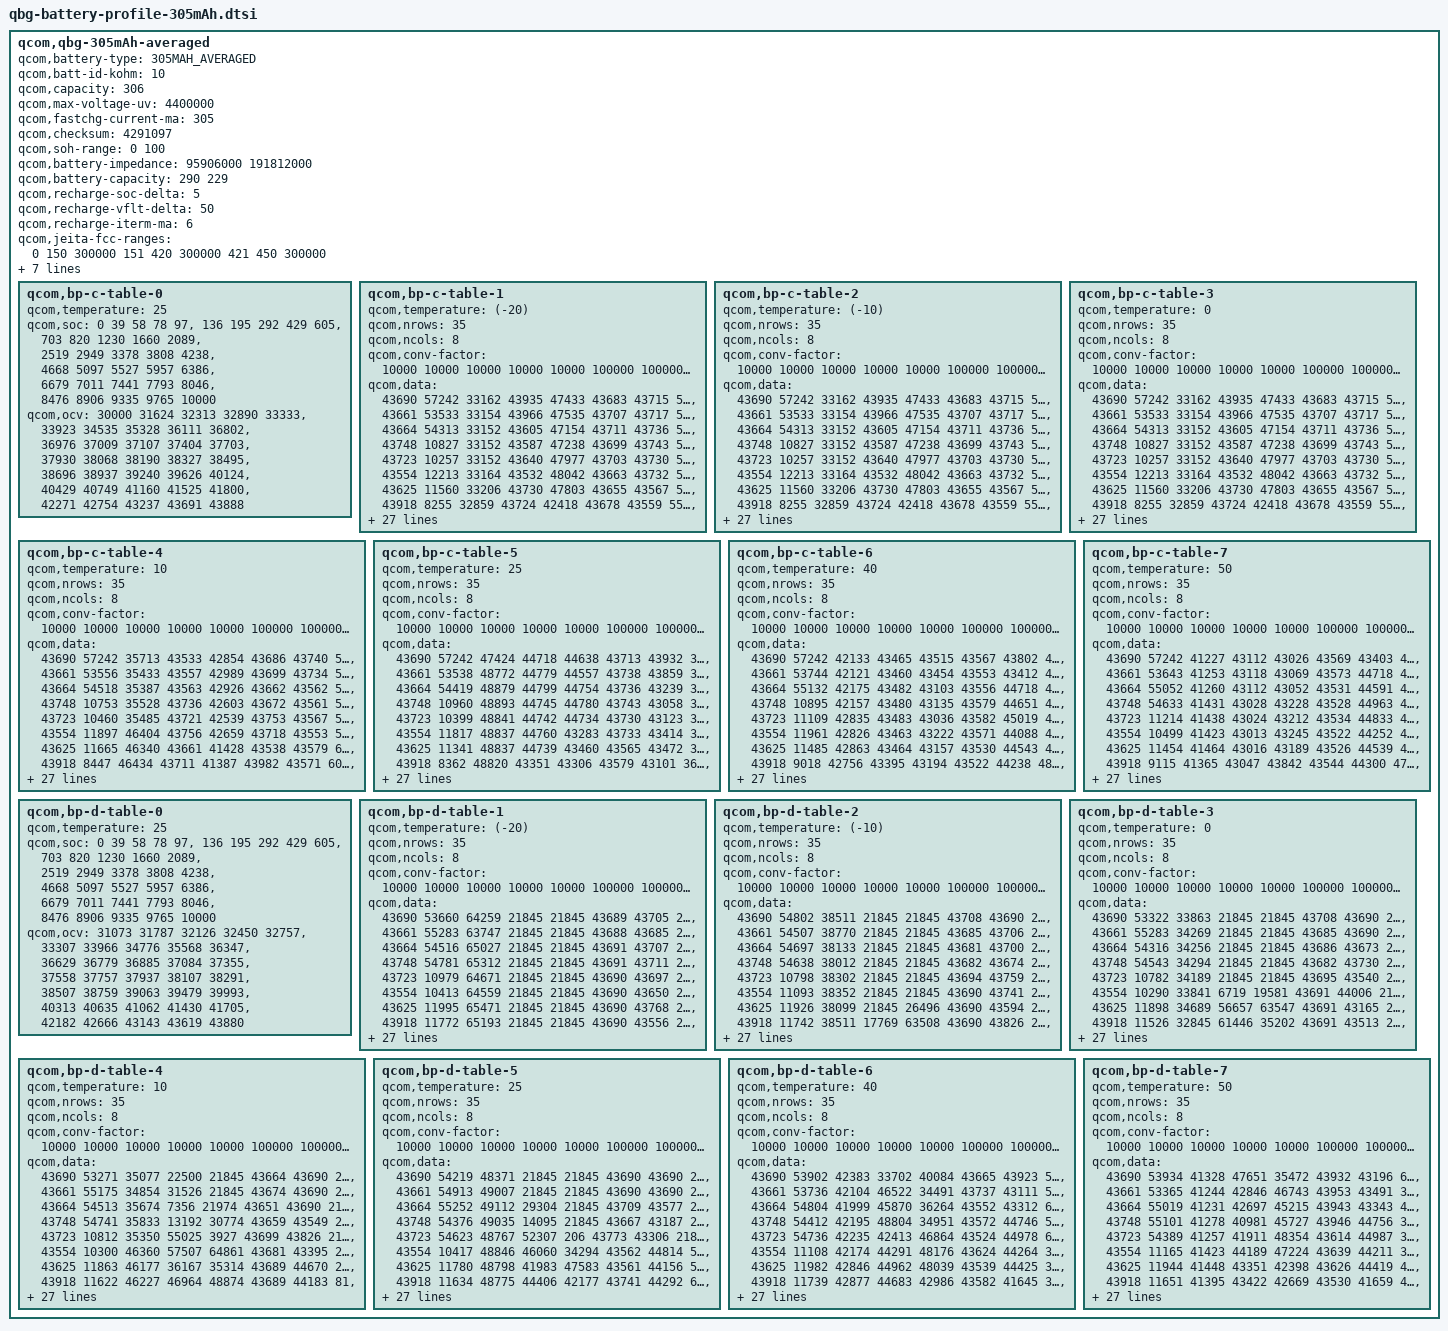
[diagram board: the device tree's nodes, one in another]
qcom,qbg-305mAh-averaged {
	qcom,battery-type = "305MAH_AVERAGED";
	qcom,batt-id-kohm = <10>;
	qcom,capacity = <306>;
	qcom,max-voltage-uv = <4400000>;
	qcom,fastchg-current-ma = <305>;
	qcom,checksum = <4291097>; /*@5, 0.005V, 4% */
	qcom,soh-range = <0 100>;
	/*Nominal_Impedance in 10nohm @ SOC 50% 25C* 0:fresh cell, 1: aged cell*/
	qcom,battery-impedance = <95906000 191812000>;
	/*Nominal_Capacity in mAh. 0: fresh cell, 1:aged cell*/
	qcom,battery-capacity = <290 229>;
	/*SOC delta (in percent) dropped from EOC SOC to enable recharge*/
	qcom,recharge-soc-delta =<5>;
	/*vfloat delta (in mV) dropped from regular vfloat in recharge*/
	qcom,recharge-vflt-delta =<50>;
	/*termination current (in mA) in recharge*/
	qcom,recharge-iterm-ma = <6>;

	qcom,jeita-fcc-ranges = <0  150 300000
				151 420 300000
				421 450 300000>;

	qcom,jeita-fv-ranges = <0  150 4350000
				151 420 4400000
				421 450 4350000>;

	qcom,jeita-soft-fcc-ua = <156000 200000>;
	qcom,jeita-soft-fv-uv = <4350000 4350000>;

	/* COOL = 15 DegC, WARM = 45 DegC */
	qcom,jeita-soft-thresholds = <0x084E 0x02F5>;
	/* COLD = 0 DegC, HOT = 45.1 DegC */
	qcom,jeita-hard-thresholds = <0x0E46 0x02F2>;
	/* COOL = 18 DegC, WARM = 44 DegC*/
	qcom,jeita-soft-hys-thresholds = <0x0775 0x030E>;

	qcom,bp-c-table-0 {
		qcom,temperature = <25>;
		qcom,soc = <    0    39    58    78    97>,
			<  136   195   292   429   605>,
			<  703   820  1230  1660  2089>,
			< 2519  2949  3378  3808  4238>,
			< 4668  5097  5527  5957  6386>,
			< 6679  7011  7441  7793  8046>,
			< 8476  8906  9335  9765 10000>;
		qcom,ocv = <30000 31624 32313 32890 33333>,
			<33923 34535 35328 36111 36802>,
			<36976 37009 37107 37404 37703>,
			<37930 38068 38190 38327 38495>,
			<38696 38937 39240 39626 40124>,
			<40429 40749 41160 41525 41800>,
			<42271 42754 43237 43691 43888>;
	};

	qcom,bp-c-table-1 {
		qcom,temperature = <(-20)>;
		qcom,nrows = <35>;
		qcom,ncols = <8>;
		qcom,conv-factor = <10000 10000 10000 10000 10000 100000 100000 10000>;
		qcom,data = <43690 57242 33162 43935 47433 43683 43715 55044>,
			<43661 53533 33154 43966 47535 43707 43717 53512>,
			<43664 54313 33152 43605 47154 43711 43736 53256>,
			<43748 10827 33152 43587 47238 43699 43743 54029>,
			<43723 10257 33152 43640 47977 43703 43730 53790>,
			<43554 12213 33164 43532 48042 43663 43732 56388>,
			<43625 11560 33206 43730 47803 43655 43567 56850>,
			<43918  8255 32859 43724 42418 43678 43559 55529>,
			<43783  9997 33173 43744 42220 43753 43583 56047>,
			<43255 15048 33252 43672 42915 43765 43581 50963>,
			<43029 14912 33276 43648 42942 43712 43576 50743>,
			<43422 15280 33244 43698 43005 43534 43579 49501>,
			<44644 15111 33212 43659 42051 43576 43570 50814>,
			<44246 14406 33270 43675 48101 43712 43577 50428>,
			<41603 16039 33087 43666 47963 43760 43570 50947>,
			<41853 15987 33222 43759 47130 43751 43577 50697>,
			<41263 16376 33173 43718 47602 43670 43579 49503>,
			<42904 16145 33183 43559 48866 43674 43579 50856>,
			<42058 15543 33257 43313 47326 43664 43994 51104>,
			<47652 15573 33214 42336 41919 43716 45031 50181>,
			<47254 15760 32774 47854 41975 43719 44905 50334>,
			<47427 12947 32811 42307 41914 43719 44978 50721>,
			<48957 13263 32831 42199 41777 43719 43504 49549>,
			<48623 12326 32865 42222 41119 43718 43129 49576>,
			<45656 12574 33192 42352 41210 43713 43476 49464>,
			<45245 13834 32976 47687 41196 43713 44793 49501>,
			<45513 14161 32968 47714 41132 43718 43331 49435>,
			<47035 13682 32986 47768 41794 43738 43116 49621>,
			<46299  3001 32780 47692 41445 43728 43037 50616>,
			<46532  2216 32855 48003 42610 43743 43021 55738>,
			<35766  2306 33037 47884 48090 43713 43202 55029>,
			<34912  4057 33124 47963 48182 43713 43196 11457>,
			<36573  3528 34768 41839 36598 43753 43935 15406>,
			<35983  1015 34644 43082 33289 43655 43549  2911>,
			<36282   225 34228 43555 35807 43657 43740 13762>;
	};

	qcom,bp-c-table-2 {
		qcom,temperature = <(-10)>;
		qcom,nrows = <35>;
		qcom,ncols = <8>;
		qcom,conv-factor = <10000 10000 10000 10000 10000 100000 100000 10000>;
		qcom,data = <43690 57242 33162 43935 47433 43683 43715 55044>,
			<43661 53533 33154 43966 47535 43707 43717 53512>,
			<43664 54313 33152 43605 47154 43711 43736 53256>,
			<43748 10827 33152 43587 47238 43699 43743 54029>,
			<43723 10257 33152 43640 47977 43703 43730 53790>,
			<43554 12213 33164 43532 48042 43663 43732 56388>,
			<43625 11560 33206 43730 47803 43655 43567 56850>,
			<43918  8255 32859 43724 42418 43678 43559 55529>,
			<43783  9997 33173 43744 42220 43753 43583 56047>,
			<43255 15048 33252 43672 42915 43765 43581 50963>,
			<43029 14912 33276 43648 42942 43712 43576 50743>,
			<43422 15280 33244 43698 43005 43534 43579 49501>,
			<44644 15111 33212 43659 42051 43576 43570 50814>,
			<44246 14406 33270 43675 48101 43712 43577 50428>,
			<41603 16039 33087 43666 47963 43760 43570 50947>,
			<41853 15987 33222 43759 47130 43751 43577 50697>,
			<41263 16376 33173 43718 47602 43670 43579 49503>,
			<42904 16145 33183 43559 48866 43674 43579 50856>,
			<42058 15543 33257 43313 47326 43664 43994 51104>,
			<47652 15573 33214 42336 41919 43716 45031 50181>,
			<47254 15760 32774 47854 41975 43719 44905 50334>,
			<47427 12947 32811 42307 41914 43719 44978 50721>,
			<48957 13263 32831 42199 41777 43719 43504 49549>,
			<48623 12326 32865 42222 41119 43718 43129 49576>,
			<45656 12574 33192 42352 41210 43713 43476 49464>,
			<45245 13834 32976 47687 41196 43713 44793 49501>,
			<45513 14161 32968 47714 41132 43718 43331 49435>,
			<47035 13682 32986 47768 41794 43738 43116 49621>,
			<46299  3001 32780 47692 41445 43728 43037 50616>,
			<46532  2216 32855 48003 42610 43743 43021 55738>,
			<35766  2306 33037 47884 48090 43713 43202 55029>,
			<34912  4057 33124 47963 48182 43713 43196 11457>,
			<36573  3528 34768 41839 36598 43753 43935 15406>,
			<35983  1015 34644 43082 33289 43655 43549  2911>,
			<36282   225 34228 43555 35807 43657 43740 13762>;
	};

	qcom,bp-c-table-3 {
		qcom,temperature = <0>;
		qcom,nrows = <35>;
		qcom,ncols = <8>;
		qcom,conv-factor = <10000 10000 10000 10000 10000 100000 100000 10000>;
		qcom,data = <43690 57242 33162 43935 47433 43683 43715 55044>,
			<43661 53533 33154 43966 47535 43707 43717 53512>,
			<43664 54313 33152 43605 47154 43711 43736 53256>,
			<43748 10827 33152 43587 47238 43699 43743 54029>,
			<43723 10257 33152 43640 47977 43703 43730 53790>,
			<43554 12213 33164 43532 48042 43663 43732 56388>,
			<43625 11560 33206 43730 47803 43655 43567 56850>,
			<43918  8255 32859 43724 42418 43678 43559 55529>,
			<43783  9997 33173 43744 42220 43753 43583 56047>,
			<43255 15048 33252 43672 42915 43765 43581 50963>,
			<43029 14912 33276 43648 42942 43712 43576 50743>,
			<43422 15280 33244 43698 43005 43534 43579 49501>,
			<44644 15111 33212 43659 42051 43576 43570 50814>,
			<44246 14406 33270 43675 48101 43712 43577 50428>,
			<41603 16039 33087 43666 47963 43760 43570 50947>,
			<41853 15987 33222 43759 47130 43751 43577 50697>,
			<41263 16376 33173 43718 47602 43670 43579 49503>,
			<42904 16145 33183 43559 48866 43674 43579 50856>,
			<42058 15543 33257 43313 47326 43664 43994 51104>,
			<47652 15573 33214 42336 41919 43716 45031 50181>,
			<47254 15760 32774 47854 41975 43719 44905 50334>,
			<47427 12947 32811 42307 41914 43719 44978 50721>,
			<48957 13263 32831 42199 41777 43719 43504 49549>,
			<48623 12326 32865 42222 41119 43718 43129 49576>,
			<45656 12574 33192 42352 41210 43713 43476 49464>,
			<45245 13834 32976 47687 41196 43713 44793 49501>,
			<45513 14161 32968 47714 41132 43718 43331 49435>,
			<47035 13682 32986 47768 41794 43738 43116 49621>,
			<46299  3001 32780 47692 41445 43728 43037 50616>,
			<46532  2216 32855 48003 42610 43743 43021 55738>,
			<35766  2306 33037 47884 48090 43713 43202 55029>,
			<34912  4057 33124 47963 48182 43713 43196 11457>,
			<36573  3528 34768 41839 36598 43753 43935 15406>,
			<35983  1015 34644 43082 33289 43655 43549  2911>,
			<36282   225 34228 43555 35807 43657 43740 13762>;
	};

	qcom,bp-c-table-4 {
		qcom,temperature = <10>;
		qcom,nrows = <35>;
		qcom,ncols = <8>;
		qcom,conv-factor = <10000 10000 10000 10000 10000 100000 100000 10000>;
		qcom,data = <43690 57242 35713 43533 42854 43686 43740 58470>,
			<43661 53556 35433 43557 42989 43699 43734 59267>,
			<43664 54518 35387 43563 42926 43662 43562 59135>,
			<43748 10753 35528 43736 42603 43672 43561 57641>,
			<43723 10460 35485 43721 42539 43753 43567 57373>,
			<43554 11897 46404 43756 42659 43718 43553 58261>,
			<43625 11665 46340 43661 41428 43538 43579 60704>,
			<43918  8447 46434 43711 41387 43982 43571 60589>,
			<43783 10183 46336 43694 41015 43442 43531 61136>,
			<43255 14983 46394 43688 41822 44783 43522 59466>,
			<43029 14959 46578 43688 41738 44688 43575 60224>,
			<43422 14916 46572 43688 41841 44668 43569 60206>,
			<44644 15297 46473 43154 41827 43968 43898 59625>,
			<44246 14545 46519 41863 44885 43565 44059 61155>,
			<41603 14603 46465 41969 44264 43555 44443 59728>,
			<41853 15908 46160 41731 44193 43564 44152 59493>,
			<41263 16302 46146 41855 44208 43566 44248 60287>,
			<42904 16321 46147 41128 44185 43560 44175 60369>,
			<42058 16244 46195 41167 44231 43733 44196 60193>,
			<47652 15553 46086 40980 44460 43732 44897 60252>,
			<47254 15805 46122 41038 41679 43732 44945 59515>,
			<47427 15733 46090 41394 40998 43733 44919 60971>,
			<48957 12885 46209 41392 41024 43729 44372 61171>,
			<48623 12311 46929 41005 44104 43732 44202 38362>,
			<45656 13978 46956 40966 44239 43562 44805 38105>,
			<45245 14211 46877 41087 44138 43562 44908 37920>,
			<45513 13328 46951 41832 44210 43563 43332 38848>,
			<47035  2810 46915 41197 44171 43733 44773 38140>,
			<46299  2877 46940 41060 44251 43735 44757 38162>,
			<46532  2102 46967 41028 44132 43734 44699 60127>,
			<35766  3788 46899 41229 44332 43728 44696 59634>,
			<34912  3220 46902 42649 41815 43731 43281 60675>,
			<36573   648 46929 42683 47850 43729 43008 63899>,
			<35983   852 46174 41925 48379 43729 43882 63418>,
			<36282    91 35476 44681 48555 43767 43633 63337>;
	};

	qcom,bp-c-table-5 {
		qcom,temperature = <25>;
		qcom,nrows = <35>;
		qcom,ncols = <8>;
		qcom,conv-factor = <10000 10000 10000 10000 10000 100000 100000 10000>;
		qcom,data = <43690 57242 47424 44718 44638 43713 43932 32945>,
			<43661 53538 48772 44779 44557 43738 43859 33766>,
			<43664 54419 48879 44799 44754 43736 43239 33357>,
			<43748 10960 48893 44745 44780 43743 43058 33321>,
			<43723 10399 48841 44742 44734 43730 43123 33420>,
			<43554 11817 48837 44760 43283 43733 43414 36316>,
			<43625 11341 48837 44739 43460 43565 43472 35895>,
			<43918  8362 48820 43351 43306 43579 43101 36612>,
			<43783 10149 47437 44558 43115 43569 44623 36431>,
			<43255  9576 47361 44796 43126 43534 44740 36530>,
			<43029 15066 47384 44779 43219 43530 44973 35269>,
			<43422 14907 47362 44791 43040 43575 45000 35300>,
			<44644 14937 47581 44976 44675 43572 44817 36477>,
			<44246 14518 47607 44832 44646 43575 44139 36825>,
			<41603 14829 47612 44851 44981 43572 44427 36804>,
			<41853 16000 47591 44205 45009 43571 44316 36727>,
			<41263 15902 47491 44160 45030 43581 41713 36840>,
			<42904 16260 47534 44170 44974 43580 44315 36600>,
			<42058 16157 47218 44180 44627 43577 44433 35157>,
			<47652 15605 47200 44244 44964 43557 44078 36539>,
			<47254 15746 47208 44152 44842 43559 44834 36406>,
			<47427 12979 47130 44475 44094 43559 44649 36707>,
			<48957 13282 47165 44477 44383 43578 44742 35937>,
			<48623 12384 47311 44075 41502 43576 44177 36037>,
			<45656 13846 47311 44871 44570 43582 45041 35617>,
			<45245 14151 47307 44871 44732 43582 45041 35757>,
			<45513 13703 47346 44887 43346 43582 45009 35411>,
			<47035  2658 47334 44223 44770 43583 44928 35778>,
			<46299  2207 47252 44214 44592 43583 44597 35653>,
			<46532  2530 47263 44173 44660 43582 44756 35019>,
			<35766  4021 47258 44247 45002 43582 44552 35223>,
			<34912  3496 47294 44145 44204 43582 44556 36572>,
			<36573   591 47320 44427 41595 43577 43373 33328>,
			<35983     1 47539 44668 42550 43557 43855 34343>,
			<36282   474 48838 44588 41374 43731 43829 34533>;
	};

	qcom,bp-c-table-6 {
		qcom,temperature = <40>;
		qcom,nrows = <35>;
		qcom,ncols = <8>;
		qcom,conv-factor = <10000 10000 10000 10000 10000 100000 100000 10000>;
		qcom,data = <43690 57242 42133 43465 43515 43567 43802 48586>,
			<43661 53744 42121 43460 43454 43553 43412 48219>,
			<43664 55132 42175 43482 43103 43556 44718 48145>,
			<43748 10895 42157 43480 43135 43579 44651 48173>,
			<43723 11109 42835 43483 43036 43582 45019 48382>,
			<43554 11961 42826 43463 43222 43571 44088 48990>,
			<43625 11485 42863 43464 43157 43530 44543 49119>,
			<43918  9018 42756 43395 43194 43522 44238 48736>,
			<43783  9743 42793 43101 43187 43527 45015 48840>,
			<43255  9712 42945 43106 43190 43548 44988 47445>,
			<43029 15030 42959 43052 43868 43542 44978 47404>,
			<43422 15083 42993 43063 43842 43551 44818 47400>,
			<44644 14899 42987 43429 43500 43549 44559 49054>,
			<44246 15214 42905 43400 43517 43550 44858 49031>,
			<41603 14415 42891 43470 43319 43536 44101 48933>,
			<41853 14691 42919 43309 43271 43546 44465 48897>,
			<41263 16065 42587 43476 43270 43547 44430 49115>,
			<42904 15940 42619 43313 43465 43524 44328 49077>,
			<42058 16174 42503 43282 43508 43522 44154 49083>,
			<47652 15504 42537 43328 43475 43529 44913 49043>,
			<47254 15804 42712 44723 43377 43528 44652 48924>,
			<47427 12938 42697 44686 44753 43529 43356 48381>,
			<48957 13252 42721 44711 44636 43533 43314 48188>,
			<48623 12731 42730 43320 44638 43526 43323 48981>,
			<45656 13916 42629 43496 43009 43533 44948 47599>,
			<45245 13475 42637 43415 43008 43520 44963 47506>,
			<45513 13801 42637 43412 43026 43521 44561 47593>,
			<47035  2655 42628 43490 43448 43520 44769 47365>,
			<46299  2267 42629 43492 43471 43526 43329 48828>,
			<46532  2349 42653 43472 43320 43524 44685 48683>,
			<35766  4035 42723 43361 43332 43525 44756 49145>,
			<34912  3576 42751 43382 44583 43525 44730 48304>,
			<36573   902 42695 44672 44941 43544 44769 48514>,
			<35983   114 42608 43313 41563 43526 43115 45139>,
			<36282   265 42141 43253 44158 43539 43805 45990>;
	};

	qcom,bp-c-table-7 {
		qcom,temperature = <50>;
		qcom,nrows = <35>;
		qcom,ncols = <8>;
		qcom,conv-factor = <10000 10000 10000 10000 10000 100000 100000 10000>;
		qcom,data = <43690 57242 41227 43112 43026 43569 43403 47305>,
			<43661 53643 41253 43118 43069 43573 44718 47282>,
			<43664 55052 41260 43112 43052 43531 44591 47961>,
			<43748 54633 41431 43028 43228 43528 44963 47994>,
			<43723 11214 41438 43024 43212 43534 44833 47879>,
			<43554 10499 41423 43013 43245 43522 44252 48070>,
			<43625 11454 41464 43016 43189 43526 44539 48063>,
			<43918  9115 41365 43047 43842 43544 44300 47627>,
			<43783  9955 41355 43217 43878 43551 44289 47845>,
			<43255  9634 41377 43213 43781 43627 44387 42320>,
			<43029  9585 41387 43196 43824 43616 44109 42287>,
			<43422 15021 41055 43860 43825 43619 44105 42434>,
			<44644 15092 41029 43230 43025 43631 44641 47702>,
			<44246 15150 41034 43200 43033 43625 44918 47734>,
			<41603 14337 41086 43203 43089 43616 44202 48056>,
			<41853 14628 41064 43218 43402 43627 44887 48025>,
			<41263 16022 40975 43209 43396 43625 44811 48045>,
			<42904 15995 41005 43042 43027 43536 44082 47625>,
			<42058 16346 41176 43022 43119 43551 44900 47636>,
			<47652 15492 41162 43114 43434 43524 44571 48033>,
			<47254 15803 41188 43105 43481 43524 43279 47915>,
			<47427 12943 41108 43121 43378 43546 43519 47937>,
			<48957 13265 41093 43122 43333 43545 43501 47966>,
			<48623 12682 41097 43219 43300 43538 43458 48045>,
			<45656 13904 41138 43190 43157 43541 44746 42470>,
			<45245 13484 41150 43187 43232 43624 44726 42491>,
			<45513 13806 41145 43166 43254 43627 44768 42451>,
			<47035  2647 41139 43225 43044 43626 44548 42323>,
			<46299  2257 41096 43055 43125 43540 44738 47861>,
			<46532  2367 41102 43042 43407 43541 44686 47621>,
			<35766  4054 41088 43060 43320 43543 43359 48021>,
			<34912  3528 41112 43108 43329 43537 44681 47997>,
			<36573   914 41108 43094 44581 43626 44686 47213>,
			<35983   117 40995 43438 44225 43624 43457 48705>,
			<36282   263 41340 43829 44176 43645 43807 48659>;
	};

	qcom,bp-d-table-0 {
		qcom,temperature = <25>;
		qcom,soc = <    0    39    58    78    97>,
			<  136   195   292   429   605>,
			<  703   820  1230  1660  2089>,
			< 2519  2949  3378  3808  4238>,
			< 4668  5097  5527  5957  6386>,
			< 6679  7011  7441  7793  8046>,
			< 8476  8906  9335  9765 10000>;
		qcom,ocv = <31073 31787 32126 32450 32757>,
			<33307 33966 34776 35568 36347>,
			<36629 36779 36885 37084 37355>,
			<37558 37757 37937 38107 38291>,
			<38507 38759 39063 39479 39993>,
			<40313 40635 41062 41430 41705>,
			<42182 42666 43143 43619 43880>;
	};

	qcom,bp-d-table-1 {
		qcom,temperature = <(-20)>;
		qcom,nrows = <35>;
		qcom,ncols = <8>;
		qcom,conv-factor = <10000 10000 10000 10000 10000 100000 100000 10000>;
		qcom,data = <43690 53660 64259 21845 21845 43689 43705 21845>,
			<43661 55283 63747 21845 21845 43688 43685 21845>,
			<43664 54516 65027 21845 21845 43691 43707 21845>,
			<43748 54781 65312 21845 21845 43691 43711 21845>,
			<43723 10979 64671 21845 21845 43690 43697 21845>,
			<43554 10413 64559 21845 21845 43690 43650 21845>,
			<43625 11995 65471 21845 21845 43690 43768 21845>,
			<43918 11772 65193 21845 21845 43690 43556 21845>,
			<43783  9046 63525 21845 12654 43690 43541 21845>,
			<43255  9875 64334 21845 62536 43690 43642 21845>,
			<43029 10122 64245 21845 64090 43690 43632 21845>,
			<43422 10052 58432 21845 61360 43690 43646 21845>,
			<44644  9577 58479 21845 60678 43690 43941 21845>,
			<44246 14944 58905 21845 37937 43690 43613 21845>,
			<41603 15156 57646 21845 38947 43690 43936 21845>,
			<41853 14584 57594 30648 33702 43691 43917 21845>,
			<41263 14427 60725 27562 36567 43691 43908 21845>,
			<42904 14628 60593  3502 35555 43691 44003 21845>,
			<42058 16013 60942  9504 46887 43691 44024 21845>,
			<47652 15979 59707 54774 45349 43691 44020 21845>,
			<47254 16375 59901 55359 45899 43691 43992 21845>,
			<47427 16213 59745 52773 45785 43691 43987 21845>,
			<48957 15390 59604 61929 48535 43691 43813 21845>,
			<48623 15678 59596 61556 48189 43691 43885 21845>,
			<45656 12909 60290 61479 48571 43691 43146 21845>,
			<45245 13157 59995 61550 45702 43691 43256 21845>,
			<45513 12699 59988 63155 45060 43691 43042 21845>,
			<47035 14233 60017 52167 46878 43691 43300 21845>,
			<46299 13643 60023 49709 33362 43691 44591 21845>,
			<46532  3038 59973 49605 33792 43691 44671 21845>,
			<35766  2091 60209 49630 33206 43691 43171 21845>,
			<34912  3638 60014 53309 35892 43691 43236 21845>,
			<36573  3469 59923  8750 35237 43691 43149 21845>,
			<35983   186 60411 14552 35339 43691 43993 21845>,
			<36282   379 60263 15528 46403 43691 43599 21845>;
	};

	qcom,bp-d-table-2 {
		qcom,temperature = <(-10)>;
		qcom,nrows = <35>;
		qcom,ncols = <8>;
		qcom,conv-factor = <10000 10000 10000 10000 10000 100000 100000 10000>;
		qcom,data = <43690 54802 38511 21845 21845 43708 43690 21845>,
			<43661 54507 38770 21845 21845 43685 43706 21845>,
			<43664 54697 38133 21845 21845 43681 43700 21845>,
			<43748 54638 38012 21845 21845 43682 43674 21845>,
			<43723 10798 38302 21845 21845 43694 43759 21845>,
			<43554 11093 38352 21845 21845 43690 43741 21845>,
			<43625 11926 38099 21845 26496 43690 43594 21845>,
			<43918 11742 38511 17769 63508 43690 43826 21845>,
			<43783  8197 36957  6979 33067 43690 43253 21845>,
			<43255 10134 37434 11872 46839 43691 43115 21845>,
			<43029  9351 40418 55369 45818 43691 43080 21845>,
			<43422  9308 40097 53114 48256 43691 43116 21845>,
			<44644 15047 40617 51903 45701 43691 43232 21845>,
			<44246 15336 39176 63993 47360 43691 43165 21845>,
			<41603 15195 39341 57419 47910 43691 43195 21845>,
			<41853 14393 40628 60164 47721 43691 43851 21845>,
			<41263 14745 39321 38593 47752 43688 43865 21845>,
			<42904 14701 39386 40090 47661 43688 43880 21678>,
			<42058 16115 40618 39879 47661 43688 43805 23876>,
			<47652 15943 39269 34621 47760 43688 43797 22748>,
			<47254 16163 39392 32897 47752 43688 43880 17639>,
			<47427 15509 39233 33481 47846 43688 43883 17982>,
			<48957 15770 40653 33286 42310 43688 43143 17979>,
			<48623 13013 39191 33379 47966 43688 43066 18219>,
			<45656 13140 39385 33336 48818 43688 43220 17499>,
			<45245 12787 39380 32865 48374 43688 43413 22649>,
			<45513 14314 39185 39738 45069 43688 44835 22280>,
			<47035 13569 39340 39696 36710 43688 43349 21845>,
			<46299  2657 39328 38978 36513 43688 43041 21845>,
			<46532  2853 39348 40563 35809 43688 43194 21845>,
			<35766  2519 39310 38436 46217 43688 43221 21845>,
			<34912  3883 38978 61153 46097 43688 43206 21845>,
			<36573  3351 39018 58953 46669 43688 43165 21845>,
			<35983   149 38922 64705 48475 43691 43892 21845>,
			<36282   278 38920 61786 48986 43691 43803 21845>;
	};

	qcom,bp-d-table-3 {
		qcom,temperature = <0>;
		qcom,nrows = <35>;
		qcom,ncols = <8>;
		qcom,conv-factor = <10000 10000 10000 10000 10000 100000 100000 10000>;
		qcom,data = <43690 53322 33863 21845 21845 43708 43690 21845>,
			<43661 55283 34269 21845 21845 43685 43690 21845>,
			<43664 54316 34256 21845 21845 43686 43673 21845>,
			<43748 54543 34294 21845 21845 43682 43730 21845>,
			<43723 10782 34189 21845 21845 43695 43540 21845>,
			<43554 10290 33841  6719 19581 43691 44006 21845>,
			<43625 11898 34689 56657 63547 43691 43165 21845>,
			<43918 11526 32845 61446 35202 43691 43513 21845>,
			<43783  8312 33572 38179 48098 43691 43379 21594>,
			<43255 10006 33686 40556 42268 43691 44774 17106>,
			<43029  9219 33700 39137 42289 43691 43343 20084>,
			<43422  9717 33316 34286 42425 43691 43404 19116>,
			<44644 15062 36217 39155 42200 43691 43256 19098>,
			<44246 15246 36132 33160 41293 43691 43188 30752>,
			<41603 15172 33415 36549 41325 43688 43232 27956>,
			<41853 14444 36216 46143 42557 43688 43050  5309>,
			<41263 14786 33442 45669 42558 43688 43236  7830>,
			<42904 14683 36160 48664 42559 43688 43197  1950>,
			<42058 16088 36183 47657 42931 43689 43881   701>,
			<47652 15953 33454 42987 42970 43689 43791  2362>,
			<47254 16138 36198 42505 42912 43689 43881 13587>,
			<47427 15403 36193 42244 42639 43689 43226 14166>,
			<48957 15645 33414 47258 42212 43694 43127 13661>,
			<48623 13232 33411 48814 47742 43694 43123  2532>,
			<45656 12343 33436 48939 47339 43692 43131  3977>,
			<45245 14050 33522 48174 48368 43701 43319   311>,
			<45513 13314 33323 48604 46167 43721 44868  4246>,
			<47035 13695 36319 48194 46605 43774 43038  7383>,
			<46299  2962 36155 46822 48393 43750 43361  4642>,
			<46532  2301 36101 46419 49096 43756 44559  4387>,
			<35766  3748 36350 46384 48252 43678 43504  5425>,
			<34912  3246 36279 35769 48415 43675 43440 28174>,
			<36573   672 36322 36309 48558 43699 43048 24705>,
			<35983   237 36172 39178 48677 43690 43998 31375>,
			<36282   309 33509 37768 47195 43690 43585 31013>;
	};

	qcom,bp-d-table-4 {
		qcom,temperature = <10>;
		qcom,nrows = <35>;
		qcom,ncols = <8>;
		qcom,conv-factor = <10000 10000 10000 10000 10000 100000 100000 10000>;
		qcom,data = <43690 53271 35077 22500 21845 43664 43690 21845>,
			<43661 55175 34854 31526 21845 43674 43690 21845>,
			<43664 54513 35674  7356 21974 43651 43690 21845>,
			<43748 54741 35833 13192 30774 43659 43549 21845>,
			<43723 10812 35350 55025  3927 43699 43826 21845>,
			<43554 10300 46360 57507 64861 43681 43395 21845>,
			<43625 11863 46177 36167 35314 43689 44670 26318>,
			<43918 11622 46227 46964 48874 43689 44183    81>,
			<43783  8301 46261 48620 42875 43689 44663 12523>,
			<43255 10014 46935 48002 42614 43689 43488 10129>,
			<43029  9339 46959 47988 42924 43694 43290  8490>,
			<43422  9513 46873 42332 42530 43694 43123  8719>,
			<44644 15085 46992 42601 41093 43694 43235 11942>,
			<44246 15272 47011 42578 41498 43693 43084 56599>,
			<41603 14504 46976 41110 41773 43709 43434 50432>,
			<41853 14414 47078 41145 44352 43743 44210 50116>,
			<41263 14810 47081 41943 44097 43734 45020 51453>,
			<42904 14709 47050 41679 44258 43563 44716 61813>,
			<42058 16074 47007 41703 44806 43560 44710 64931>,
			<47652 16266 47030 41560 44198 43560 44912 64648>,
			<47254 15540 47094 41735 41641 43561 44444 64959>,
			<47427 15805 47101 41149 41538 43554 44211 64920>,
			<48957 13036 46985 41384 41127 43560 44825 62142>,
			<48623 13062 47037 42658 41218 43734 45033 61588>,
			<45656 12751 47060 42824 42219 43741 44812 62670>,
			<45245 13944 47059 41996 47951 43743 45024 51312>,
			<45513 13374 47012 42380 48566 43736 43300 52568>,
			<47035  2737 46709 47294 47275 43721 43488 52316>,
			<46299  3028 46710 47279 48111 43773 43420 52578>,
			<46532  2104 46708 47987 48038 43769 43416 50102>,
			<35766  3800 47020 47296 47747 43775 43298 49554>,
			<34912  3273 47018 47150 47850 43768 43463 51026>,
			<36573   767 46689 47245 42096 43751 43415 50437>,
			<35983   245 46837 48031 41435 43757 43095 55964>,
			<36282   289 46721 47688 41007 43753 43133 50459>;
	};

	qcom,bp-d-table-5 {
		qcom,temperature = <25>;
		qcom,nrows = <35>;
		qcom,ncols = <8>;
		qcom,conv-factor = <10000 10000 10000 10000 10000 100000 100000 10000>;
		qcom,data = <43690 54219 48371 21845 21845 43690 43690 21845>,
			<43661 54913 49007 21845 21845 43690 43690 21845>,
			<43664 55252 49112 29304 21845 43709 43577 21845>,
			<43748 54376 49035 14095 21845 43667 43187 21845>,
			<43723 54623 48767 52307   206 43773 43306 21845>,
			<43554 10417 48846 46060 34294 43562 44814 56827>,
			<43625 11780 48798 41983 47583 43561 44156 58008>,
			<43918 11634 48775 44406 42177 43741 44292 60060>,
			<43783  8282 47486 44470 41913 43729 44378 37438>,
			<43255 10065 47457 44045 44442 43565 44323 39292>,
			<43029  9663 47397 44133 44300 43552 44125 39294>,
			<43422  9473 47413 44057 44266 43554 44902 39755>,
			<44644 15039 47405 45020 44676 43567 44643 34664>,
			<44246 14966 47593 44942 44777 43577 44610 32807>,
			<41603 15169 47563 44934 44714 43569 44915 33463>,
			<41853 14364 47196 44965 43367 43530 44240 36070>,
			<41263 14807 47547 45004 44663 43573 44377 36281>,
			<42904 16027 47521 45021 44816 43529 44536 36227>,
			<42058 15985 47531 45012 44861 43528 44256 35896>,
			<47652 16185 47223 44836 44985 43530 44198 36654>,
			<47254 15553 47208 44813 44649 43572 44186 36449>,
			<47427 15821 47215 44816 44547 43569 44283 36566>,
			<48957 12861 47116 44925 44985 43570 44198 36429>,
			<48623 12445 47104 44071 44510 43581 44894 36162>,
			<45656 13971 47315 44434 41441 43580 44690 34454>,
			<45245 14291 47301 44332 41440 43577 43519 34545>,
			<45513 13329 47322 44393 41915 43554 43076 32803>,
			<47035  2764 47302 44387 44525 43560 43320 33769>,
			<46299  2940 47308 44296 44042 43563 44707 33307>,
			<46532  2115 47307 44504 44239 43563 44773 33501>,
			<35766  3692 47301 44425 44179 43564 44569 33511>,
			<34912  3072 47308 44128 44275 43555 44553 33335>,
			<36573   557 47142 44248 44167 43556 44760 33295>,
			<35983   201 47174 44214 44810 43582 44682 33493>,
			<36282   450 47543 44888 45049 43581 43347 33510>;
	};

	qcom,bp-d-table-6 {
		qcom,temperature = <40>;
		qcom,nrows = <35>;
		qcom,ncols = <8>;
		qcom,conv-factor = <10000 10000 10000 10000 10000 100000 100000 10000>;
		qcom,data = <43690 53902 42383 33702 40084 43665 43923 53967>,
			<43661 53736 42104 46522 34491 43737 43111 51998>,
			<43664 54804 41999 45870 36264 43552 43312 65357>,
			<43748 54412 42195 48804 34951 43572 44746 57387>,
			<43723 54736 42235 42413 46864 43524 44978 60067>,
			<43554 11108 42174 44291 48176 43624 44264 39592>,
			<43625 11982 42846 44962 48039 43539 44425 35956>,
			<43918 11739 42877 44683 42986 43582 41645 35605>,
			<43783  8392 42815 43388 41558 43577 41494 46618>,
			<43255 10133 42998 43291 44765 43528 41582 48436>,
			<43029  9255 42983 43387 44704 43522 41611 48531>,
			<43422  9677 42985 43342 43274 43522 44819 48255>,
			<44644  9595 42892 43448 43245 43526 44856 48889>,
			<44246 14889 42580 43435 43220 43537 44925 48820>,
			<41603 15161 42597 43078 43065 43539 44202 47462>,
			<41853 14528 42502 43126 43128 43539 44182 47466>,
			<41263 14821 42507 43454 43363 43626 44203 48748>,
			<42904 16004 42540 43516 44658 43627 44805 48298>,
			<42058 15943 42715 43491 44561 43626 44624 49001>,
			<47652 16141 42738 43402 43356 43543 44603 48640>,
			<47254 15569 42653 43455 43498 43551 44556 47459>,
			<47427 15839 42638 43400 43079 43524 44959 47559>,
			<48957 12811 42685 43405 43454 43524 45035 47399>,
			<48623 12432 42680 43295 44608 43547 44954 48979>,
			<45656 13956 42687 44775 44102 43525 43423 45666>,
			<45245 14287 42672 44598 44093 43520 43101 45599>,
			<45513 13322 42676 44665 44576 43575 43479 48209>,
			<47035  2789 42632 44678 43358 43580 43488 49000>,
			<46299  2923 42624 43346 43479 43581 43321 49037>,
			<46532  2169 42654 43380 43414 43571 43329 48754>,
			<35766  3588 42746 43317 43439 43574 44688 48861>,
			<34912  3130 42739 43511 43091 43531 44744 48874>,
			<36573   710 42691 43516 43085 43533 44658 48875>,
			<35983   146 42536 43505 43109 43525 44807 48839>,
			<36282   390 42533 43470 43114 43545 44199 48653>;
	};

	qcom,bp-d-table-7 {
		qcom,temperature = <50>;
		qcom,nrows = <35>;
		qcom,ncols = <8>;
		qcom,conv-factor = <10000 10000 10000 10000 10000 100000 100000 10000>;
		qcom,data = <43690 53934 41328 47651 35472 43932 43196 60132>,
			<43661 53365 41244 42846 46743 43953 43491 37497>,
			<43664 55019 41231 42697 45215 43943 43343 40560>,
			<43748 55101 41278 40981 45727 43946 44756 39496>,
			<43723 54389 41257 41911 48354 43614 44987 34720>,
			<43554 11165 41423 44189 47224 43639 44211 35992>,
			<43625 11944 41448 43351 42398 43626 44419 46439>,
			<43918 11651 41395 43422 42669 43530 41659 45354>,
			<43783  8320 41054 43083 41872 43529 41489 45735>,
			<43255  9819 41060 43115 44692 43524 41570 47211>,
			<43029  9361 40983 43107 43398 43544 41477 47872>,
			<43422  9631 40985 43452 43428 43525 44063 47991>,
			<44644  9482 41010 43160 43851 43541 45010 42279>,
			<44246 15096 41173 43185 43149 43622 44632 42296>,
			<41603 15299 41160 43239 43258 43646 44074 42341>,
			<41853 14485 41197 43149 43221 43623 44891 42346>,
			<41263 14734 41118 43166 43452 43621 45028 47847>,
			<42904 16052 41102 43237 44787 43647 44764 47921>,
			<42058 15936 41146 43158 44773 43644 43360 48091>,
			<47652 16142 41812 43162 43509 43643 43390 47818>,
			<47254 15575 41819 43258 43023 43622 44665 42269>,
			<47427 15824 41807 43263 43263 43628 44839 42443>,
			<48957 12802 41840 43210 43051 43626 44839 42297>,
			<48623 12437 41851 43116 44697 43541 44622 47879>,
			<45656 13954 41850 43477 44990 43536 43518 47556>,
			<45245 14326 41850 43275 44668 43545 43395 47609>,
			<45513 13374 41854 43278 43511 43523 43373 47951>,
			<47035  2796 41841 43314 43221 43523 44984 48063>,
			<46299  2834 41800 43394 43223 43535 44789 47662>,
			<46532  2144 41795 43119 43051 43529 43365 47770>,
			<35766  3599 41811 43058 43153 43524 44783 42340>,
			<34912  3106 41135 43253 43136 43545 44751 42285>,
			<36573   715 41150 43161 43137 43542 44755 42441>,
			<35983   130 41090 43199 43158 43616 44591 42441>,
			<36282   434 41112 43172 43237 43642 44591 42452>;
	};
};
